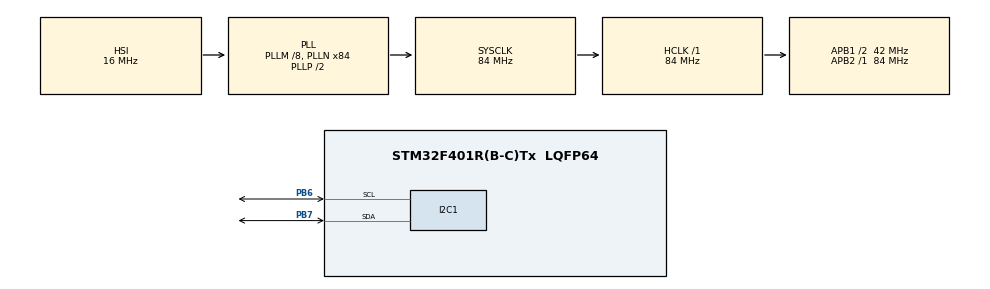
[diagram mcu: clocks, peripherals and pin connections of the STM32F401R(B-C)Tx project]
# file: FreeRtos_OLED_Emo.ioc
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Dma.I2C1_RX.0.Direction=DMA_PERIPH_TO_MEMORY
Dma.I2C1_RX.0.FIFOMode=DMA_FIFOMODE_DISABLE
Dma.I2C1_RX.0.Instance=DMA1_Stream0
Dma.I2C1_RX.0.MemDataAlignment=DMA_MDATAALIGN_BYTE
Dma.I2C1_RX.0.MemInc=DMA_MINC_ENABLE
Dma.I2C1_RX.0.Mode=DMA_NORMAL
Dma.I2C1_RX.0.PeriphDataAlignment=DMA_PDATAALIGN_BYTE
Dma.I2C1_RX.0.PeriphInc=DMA_PINC_DISABLE
Dma.I2C1_RX.0.Priority=DMA_PRIORITY_VERY_HIGH
Dma.I2C1_TX.1.Direction=DMA_MEMORY_TO_PERIPH
Dma.I2C1_TX.1.FIFOMode=DMA_FIFOMODE_DISABLE
Dma.I2C1_TX.1.Instance=DMA1_Stream6
Dma.I2C1_TX.1.MemDataAlignment=DMA_MDATAALIGN_BYTE
Dma.I2C1_TX.1.MemInc=DMA_MINC_ENABLE
Dma.I2C1_TX.1.Mode=DMA_NORMAL
Dma.I2C1_TX.1.PeriphDataAlignment=DMA_PDATAALIGN_BYTE
Dma.I2C1_TX.1.PeriphInc=DMA_PINC_DISABLE
Dma.I2C1_TX.1.Priority=DMA_PRIORITY_VERY_HIGH
Dma.Request0=I2C1_RX
Dma.Request1=I2C1_TX
FREERTOS.INCLUDE_xSemaphoreGetMutexHolder=1
FREERTOS.Tasks01=defaultTask,24,128,StartDefaultTask,Default,NULL,Dynamic,NULL,NULL
I2C1.I2C_Mode=I2C_Fast
Mcu.Family=STM32F4
Mcu.Name=STM32F401R(B-C)Tx
Mcu.Package=LQFP64
NVIC.DMA1_Stream0_IRQn=true\:5\:0\:false\:false\:true\:true\:false\:true\:true
NVIC.DMA1_Stream6_IRQn=true\:5\:0\:false\:false\:true\:true\:false\:true\:true
NVIC.I2C1_EV_IRQn=true\:5\:0\:false\:false\:true\:true\:true\:true\:true
NVIC.PriorityGroup=NVIC_PRIORITYGROUP_4
NVIC.TIM1_BRK_TIM9_IRQn=true\:15\:0\:false\:false\:true\:false\:false\:true\:true
NVIC.TIM2_IRQn=true\:5\:0\:false\:false\:true\:true\:true\:true\:true
NVIC.TimeBase=TIM1_BRK_TIM9_IRQn
NVIC.TimeBaseIP=TIM9
PA13.Mode=Serial_Wire
PA13.Signal=SYS_JTMS-SWDIO
PA14.Mode=Serial_Wire
PA14.Signal=SYS_JTCK-SWCLK
PB6.GPIO_Pu=GPIO_PULLUP
PB6.Mode=I2C
PB6.Signal=I2C1_SCL
PB7.GPIO_Pu=GPIO_PULLUP
PB7.Mode=I2C
PB7.Signal=I2C1_SDA
PC14-OSC32_IN.Mode=LSE-External-Oscillator
PC14-OSC32_IN.Signal=RCC_OSC32_IN
PC15-OSC32_OUT.Mode=LSE-External-Oscillator
PC15-OSC32_OUT.Signal=RCC_OSC32_OUT
PH0\ -\ OSC_IN.Mode=HSE-External-Oscillator
PH0\ -\ OSC_IN.Signal=RCC_OSC_IN
PH1\ -\ OSC_OUT.Mode=HSE-External-Oscillator
PH1\ -\ OSC_OUT.Signal=RCC_OSC_OUT
ProjectManager.HeapSize=0x200
ProjectManager.StackSize=0x400
ProjectManager.TargetToolchain=MDK-ARM V5.32
RCC.48MHZClocksFreq_Value=42000000
RCC.AHBFreq_Value=84000000
RCC.APB1CLKDivider=RCC_HCLK_DIV2
RCC.APB1Freq_Value=42000000
RCC.APB1TimFreq_Value=84000000
RCC.APB2Freq_Value=84000000
RCC.APB2TimFreq_Value=84000000
RCC.CortexFreq_Value=84000000
RCC.HCLKFreq_Value=84000000
RCC.HSE_VALUE=25000000
RCC.HSI_VALUE=16000000
RCC.PLLM=8
RCC.PLLN=84
RCC.SYSCLKFreq_VALUE=84000000
RCC.SYSCLKSource=RCC_SYSCLKSOURCE_PLLCLK
RCC.VCOOutputFreq_Value=168000000
TIM2.Period=1000-1
TIM2.Prescaler=84-1
VP_FREERTOS_VS_CMSIS_V2.Mode=CMSIS_V2
VP_SYS_VS_tim9.Mode=TIM9
VP_TIM2_VS_ClockSourceINT.Mode=Internal
board=custom

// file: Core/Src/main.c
/* USER CODE BEGIN Header */
/**
  ******************************************************************************
  * @file           : main.c
  * @brief          : Main program body
  ******************************************************************************
  * @attention
  *
  * Copyright (c) 2025 STMicroelectronics.
  * All rights reserved.
  *
  * This software is licensed under terms that can be found in the LICENSE file
  * in the root directory of this software component.
  * If no LICENSE file comes with this software, it is provided AS-IS.
  *
  ******************************************************************************
  */
/* USER CODE END Header */
#include "main.h"
#include "cmsis_os.h"
#include "dma.h"
#include "i2c.h"
#include "tim.h"
#include "gpio.h"

void SystemClock_Config(void);
void MX_FREERTOS_Init(void);

int main(void)
{

  /* MCU Configuration--------------------------------------------------------*/

  /* Reset of all peripherals, Initializes the Flash interface and the Systick. */
  HAL_Init();

  /* Configure the system clock */
  SystemClock_Config();

  /* Initialize all configured peripherals */
  MX_GPIO_Init();
  MX_DMA_Init();
  MX_I2C1_Init();
  MX_TIM2_Init();

  /* Init scheduler */
  osKernelInitialize();  /* Call init function for freertos objects (in cmsis_os2.c) */
  MX_FREERTOS_Init();

  /* Start scheduler */
  osKernelStart();

  /* We should never get here as control is now taken by the scheduler */

  /* Infinite loop */
  while (1)
  {

  }
}

void SystemClock_Config(void)
{
  RCC_OscInitTypeDef RCC_OscInitStruct = {0};
  RCC_ClkInitTypeDef RCC_ClkInitStruct = {0};

  /** Configure the main internal regulator output voltage
  */
  __HAL_RCC_PWR_CLK_ENABLE();
  __HAL_PWR_VOLTAGESCALING_CONFIG(PWR_REGULATOR_VOLTAGE_SCALE2);

  /** Initializes the RCC Oscillators according to the specified parameters
  * in the RCC_OscInitTypeDef structure.
  */
  RCC_OscInitStruct.OscillatorType = RCC_OSCILLATORTYPE_HSI;
  RCC_OscInitStruct.HSIState = RCC_HSI_ON;
  RCC_OscInitStruct.HSICalibrationValue = RCC_HSICALIBRATION_DEFAULT;
  RCC_OscInitStruct.PLL.PLLState = RCC_PLL_ON;
  RCC_OscInitStruct.PLL.PLLSource = RCC_PLLSOURCE_HSI;
  RCC_OscInitStruct.PLL.PLLM = 8;
  RCC_OscInitStruct.PLL.PLLN = 84;
  RCC_OscInitStruct.PLL.PLLP = RCC_PLLP_DIV2;
  RCC_OscInitStruct.PLL.PLLQ = 4;
  if (HAL_RCC_OscConfig(&RCC_OscInitStruct) != HAL_OK)
  {
    Error_Handler();
  }

  /** Initializes the CPU, AHB and APB buses clocks
  */
  RCC_ClkInitStruct.ClockType = RCC_CLOCKTYPE_HCLK|RCC_CLOCKTYPE_SYSCLK
                              |RCC_CLOCKTYPE_PCLK1|RCC_CLOCKTYPE_PCLK2;
  RCC_ClkInitStruct.SYSCLKSource = RCC_SYSCLKSOURCE_PLLCLK;
  RCC_ClkInitStruct.AHBCLKDivider = RCC_SYSCLK_DIV1;
  RCC_ClkInitStruct.APB1CLKDivider = RCC_HCLK_DIV2;
  RCC_ClkInitStruct.APB2CLKDivider = RCC_HCLK_DIV1;

  if (HAL_RCC_ClockConfig(&RCC_ClkInitStruct, FLASH_LATENCY_2) != HAL_OK)
  {
    Error_Handler();
  }
}

void HAL_TIM_PeriodElapsedCallback(TIM_HandleTypeDef *htim)
{
  if (htim->Instance == TIM9)
  {
    HAL_IncTick();
  }
}

void Error_Handler(void)
{
  __disable_irq();
  while (1)
  {
  }
}

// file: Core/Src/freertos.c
/* USER CODE BEGIN Header */
/**
  ******************************************************************************
  * File Name          : freertos.c
  * Description        : Code for freertos applications
  ******************************************************************************
  * @attention
  *
  * Copyright (c) 2025 STMicroelectronics.
  * All rights reserved.
  *
  * This software is licensed under terms that can be found in the LICENSE file
  * in the root directory of this software component.
  * If no LICENSE file comes with this software, it is provided AS-IS.
  *
  ******************************************************************************
  */
/* USER CODE END Header */

#include "FreeRTOS.h"
#include "task.h"
#include "main.h"
#include "cmsis_os.h"

/* USER CODE BEGIN Includes */
#include "queue.h"
#include "timers.h"
#include "semphr.h"
#include "I2C_DMA.h"
#include "MyTask.h"
/* USER CODE END Includes */

/* Definitions for defaultTask */
osThreadId_t defaultTaskHandle;
const osThreadAttr_t defaultTask_attributes = {
  .name = "defaultTask",
  .stack_size = 128 * 4,
  .priority = (osPriority_t) osPriorityNormal,
};

/* USER CODE BEGIN FunctionPrototypes */

extern TimerHandle_t Timer1;
extern QueueHandle_t I2C1_DMAQueue;
extern TaskHandle_t  I2C1_TaskHandle;
extern SemaphoreHandle_t I2C1_DMA_IDLE;

void vApplicationStackOverflowHook( TaskHandle_t xTask, char * pcTaskName ){
  while (1)
  {

  }

}

void vApplicationMallocFailedHook( void ){
  while (1)
  {

  }

}

/* USER CODE END FunctionPrototypes */

void StartDefaultTask(void *argument);

void MX_FREERTOS_Init(void); /* (MISRA C 2004 rule 8.1) */

void MX_FREERTOS_Init(void) {

  /* Create the thread(s) */
  /* creation of defaultTask */
  //defaultTaskHandle = osThreadNew(StartDefaultTask, NULL, &defaultTask_attributes);
  uint8_t ID = 0;
  Timer1 = xTimerCreate("Timer1", 1, 1, &ID, MyTimerCallback);
  I2C1_DMAQueue = xQueueCreate(20, sizeof(Struct_I2C_TransData));
  I2C1_DMA_IDLE = xSemaphoreCreateBinary();

  xTaskCreate(I2C1_DMA_TransTask, "I2C_TransTask", 256, NULL, 24, &I2C1_TaskHandle);

  xSemaphoreGive(I2C1_DMA_IDLE);
  xTimerStart(Timer1, portMAX_DELAY);

}

void StartDefaultTask(void *argument)
{
  for(;;)
  {
    osDelay(1);
  }
}
